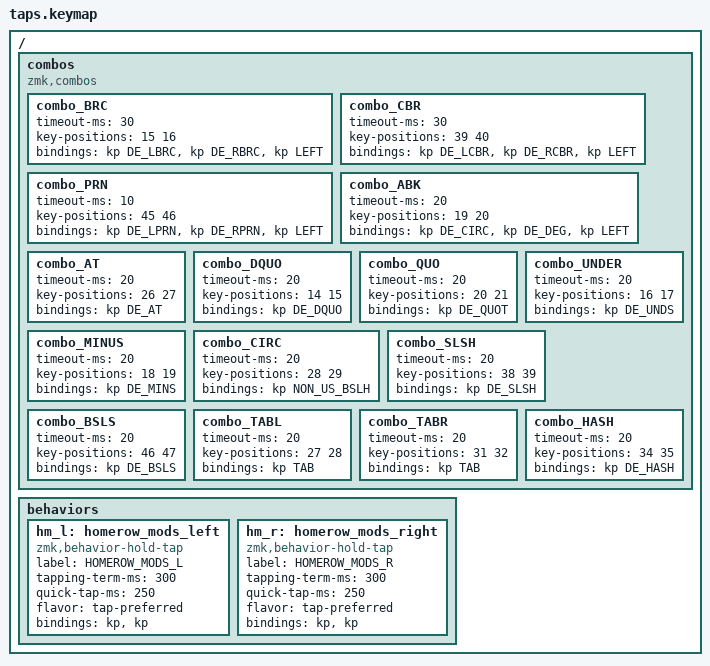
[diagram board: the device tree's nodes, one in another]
#define AS(keycode) &as LS(keycode) keycode     // Autoshift Macro - AS(Q) AS(W) AS(E) AS(R) AS(T) AS(Y) Autoshift applied for QWERTY keys
//#define HM(keycode, mods) &bhm mods keycode // HomeRow mods - HM(I, F5)
/ {
    combos {
        compatible = "zmk,combos";
        combo_BRC {
            timeout-ms = <30>;
	        key-positions = <15 16>;
            bindings = <&kp DE_LBRC &kp DE_RBRC &kp LEFT>;
        };
        combo_CBR {
            timeout-ms = <30>;
	        key-positions = <39 40>;
            bindings = <&kp DE_LCBR &kp DE_RCBR &kp LEFT>;
        };
        combo_PRN  {
            timeout-ms = <10>;
            key-positions = <45 46>;
            bindings = <&kp DE_LPRN &kp DE_RPRN &kp LEFT>;
        };
        combo_ABK {
            timeout-ms = <20>;
	        key-positions = <19 20>;
            bindings = <&kp DE_CIRC &kp DE_DEG &kp LEFT>; 
        };
        combo_AT {
            timeout-ms = <20>;
	        key-positions = <26 27>;
            bindings = <&kp DE_AT>;
        };
        combo_DQUO {
            timeout-ms = <20>;
	        key-positions = <14 15>;
            bindings = <&kp DE_DQUO>;
        };
        combo_QUO {
            timeout-ms = <20>;
	        key-positions = <20 21>;
            bindings = <&kp DE_QUOT>;
        };
        combo_UNDER {
            timeout-ms = <20>;
	        key-positions = <16 17>;
            bindings = <&kp DE_UNDS>;
        };
        combo_MINUS {
            timeout-ms = <20>;
	        key-positions = <18 19>;
            bindings = <&kp DE_MINS>;
        };
        combo_CIRC {
            timeout-ms = <20>;
	        key-positions = <28 29>;
            bindings = <&kp NON_US_BSLH>;
        };
        combo_SLSH {
            timeout-ms = <20>;
	        key-positions = <38 39>;
            bindings = <&kp DE_SLSH>;
        };
        combo_BSLS {
            timeout-ms = <20>;
	        key-positions = <46 47>;
            bindings = <&kp DE_BSLS>;
        };
        combo_TABL {
            timeout-ms = <20>;
	        key-positions = <27 28>;
            bindings = <&kp TAB>;
        };
        combo_TABR {
            timeout-ms = <20>;
	        key-positions = <31 32>;
            bindings = <&kp TAB>;
        };
        combo_HASH {
            timeout-ms = <20>;
	        key-positions = <34 35>;
            bindings = <&kp DE_HASH>;
        };
    };

    behaviors {
        hm_l: homerow_mods_left {
            compatible = "zmk,behavior-hold-tap";
            label = "HOMEROW_MODS_L";
            #binding-cells = <2>;
            tapping-term-ms = <300>;
            quick-tap-ms = <250>;
            flavor = "tap-preferred";
            bindings = <&kp>, <&kp>;
        };
        hm_r: homerow_mods_right {
            compatible = "zmk,behavior-hold-tap";
            label = "HOMEROW_MODS_R";
            #binding-cells = <2>;
            tapping-term-ms = <300>;
            quick-tap-ms = <250>;
            flavor = "tap-preferred";
            bindings = <&kp>, <&kp>;
        };
    };
};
